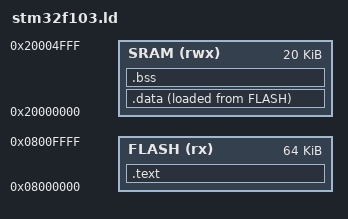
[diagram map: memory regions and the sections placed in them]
MEMORY
{
    FLASH (rx)  : ORIGIN = 0x08000000, LENGTH = 64K
    SRAM  (rwx) : ORIGIN = 0x20000000, LENGTH = 20K
}

SECTIONS
{
    .text :
    {
        KEEP(*(.vectors))
        *(.text*)
        *(.rodata*)
    } > FLASH

    .data :
    {
        _sdata = .;
        *(.data*)
        _edata = .;
    } > SRAM AT > FLASH

    _sidata = LOADADDR(.data);

    .bss :
    {
        _sbss = .;
        *(.bss*)
        *(COMMON)
        _ebss = .;
    } > SRAM

    _estack = ORIGIN(SRAM) + LENGTH(SRAM);
}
